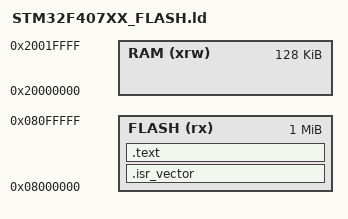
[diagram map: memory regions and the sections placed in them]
ENTRY(Reset_Handler)

MEMORY
{
  FLASH (rx)  : ORIGIN = 0x08000000, LENGTH = 1024K
  RAM   (xrw) : ORIGIN = 0x20000000, LENGTH = 128K
}

_estack = ORIGIN(RAM) + LENGTH(RAM);

SECTIONS
{
  .isr_vector :
  {
    . = ALIGN(4);
    KEEP(*(.isr_vector))
    . = ALIGN(4);
  } > FLASH

  .text :
  {
    . = ALIGN(4);
    *(.text)
    *(.text*)
    *(.rodata)
    *(.rodata*)
    . = ALIGN(4);
  } > FLASH
}
